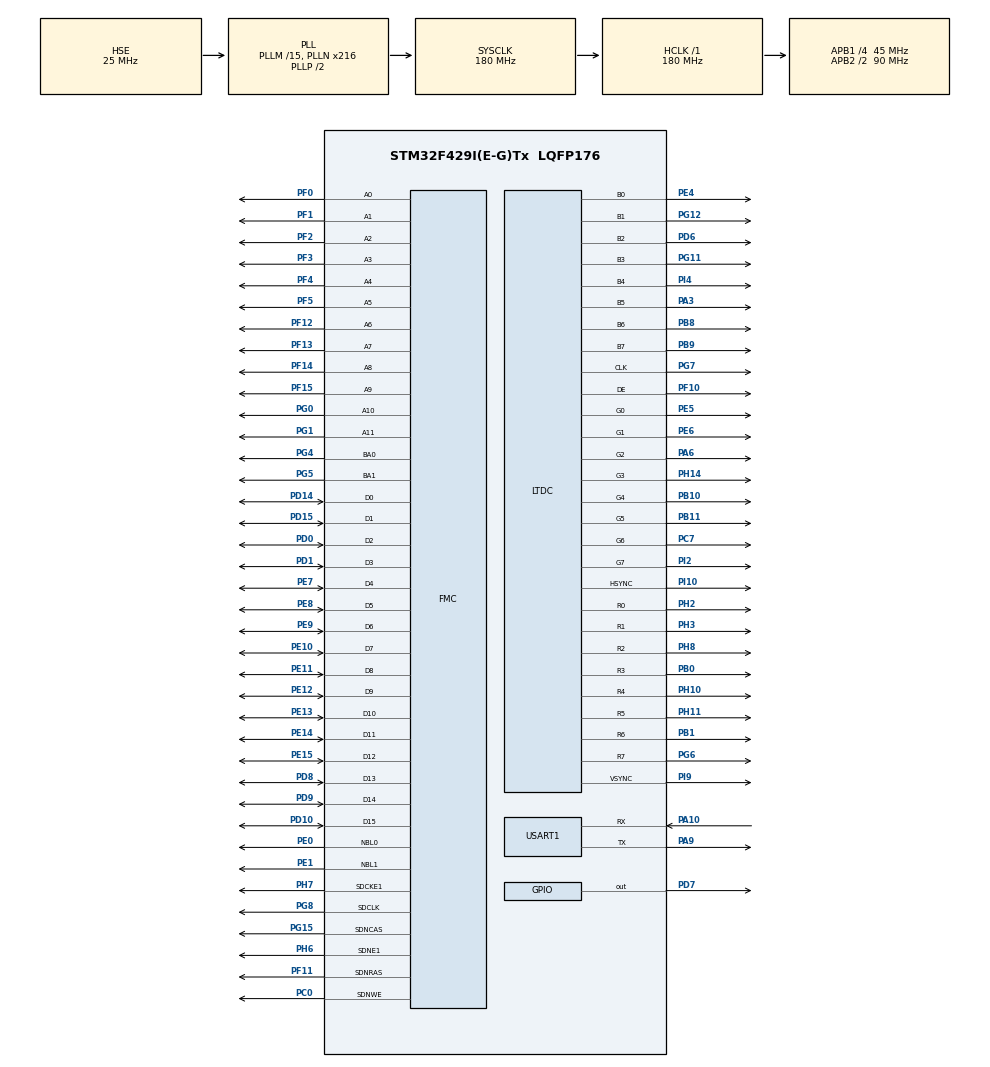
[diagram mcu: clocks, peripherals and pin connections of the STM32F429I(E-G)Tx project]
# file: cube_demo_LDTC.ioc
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DMA2D.ColorMode=DMA2D_OUTPUT_RGB565
Dma.MEMTOMEM.0.Direction=DMA_MEMORY_TO_MEMORY
Dma.MEMTOMEM.0.FIFOMode=DMA_FIFOMODE_ENABLE
Dma.MEMTOMEM.0.FIFOThreshold=DMA_FIFO_THRESHOLD_FULL
Dma.MEMTOMEM.0.Instance=DMA2_Stream0
Dma.MEMTOMEM.0.MemBurst=DMA_MBURST_SINGLE
Dma.MEMTOMEM.0.MemDataAlignment=DMA_MDATAALIGN_WORD
Dma.MEMTOMEM.0.MemInc=DMA_MINC_ENABLE
Dma.MEMTOMEM.0.Mode=DMA_NORMAL
Dma.MEMTOMEM.0.PeriphBurst=DMA_PBURST_SINGLE
Dma.MEMTOMEM.0.PeriphDataAlignment=DMA_PDATAALIGN_WORD
Dma.MEMTOMEM.0.PeriphInc=DMA_PINC_ENABLE
Dma.MEMTOMEM.0.Priority=DMA_PRIORITY_LOW
Dma.Request0=MEMTOMEM
FMC.CASLatency1=FMC_SDRAM_CAS_LATENCY_2
FMC.ExitSelfRefreshDelay1=8
FMC.LoadToActiveDelay1=2
FMC.RCDDelay1=3
FMC.RPDelay1=2
FMC.RPDelay2=2
FMC.RowCycleDelay1=7
FMC.RowCycleDelay2=7
FMC.SDClockPeriod1=FMC_SDRAM_CLOCK_PERIOD_2
FMC.SDClockPeriod2=FMC_SDRAM_CLOCK_PERIOD_2
FMC.SelfRefreshTime1=5
FMC.WriteRecoveryTime1=2
LTDC.ActiveW=800
LTDC.Alpha0_L0=0
LTDC.Alpha_L0=255
LTDC.Blue_L0=0
LTDC.FBStartAdress_L0=0xD0000000
LTDC.HBP=140
LTDC.HFP=160
LTDC.HSPolarity=LTDC_HSPOLARITY_AL
LTDC.HSync=20
LTDC.ImageHeight_L0=480
LTDC.ImageWidth_L0=800
LTDC.Layers=0
LTDC.PixelFormat_L0=LTDC_PIXEL_FORMAT_RGB565
LTDC.VBP=20
LTDC.VFP=12
LTDC.VSync=3
LTDC.WindowX1_L0=800
LTDC.WindowY1_L0=480
Mcu.Family=STM32F4
Mcu.Name=STM32F429I(E-G)Tx
Mcu.Package=LQFP176
NVIC.DMA2D_IRQn=true\:0\:0\:false\:false\:true\:true\:true
NVIC.LTDC_IRQn=true\:0\:0\:false\:false\:true\:true\:true
NVIC.PriorityGroup=NVIC_PRIORITYGROUP_4
PA10.Mode=Asynchronous
PA10.Signal=USART1_RX
PA13.Mode=Serial_Wire
PA13.Signal=SYS_JTMS-SWDIO
PA14.Mode=Serial_Wire
PA14.Signal=SYS_JTCK-SWCLK
PA3.GPIO_Speed=GPIO_SPEED_FREQ_HIGH
PA3.Mode=RGB888
PA3.Signal=LTDC_B5
PA6.GPIO_Speed=GPIO_SPEED_FREQ_HIGH
PA6.Mode=RGB888
PA6.Signal=LTDC_G2
PA9.Mode=Asynchronous
PA9.Signal=USART1_TX
PB0.GPIO_Speed=GPIO_SPEED_FREQ_HIGH
PB0.Mode=RGB888
PB0.Signal=LTDC_R3
PB1.GPIO_Speed=GPIO_SPEED_FREQ_HIGH
PB1.Mode=RGB888
PB1.Signal=LTDC_R6
PB10.GPIO_Speed=GPIO_SPEED_FREQ_HIGH
PB10.Mode=RGB888
PB10.Signal=LTDC_G4
PB11.GPIO_Speed=GPIO_SPEED_FREQ_HIGH
PB11.Mode=RGB888
PB11.Signal=LTDC_G5
PB8.GPIO_Speed=GPIO_SPEED_FREQ_HIGH
PB8.Mode=RGB888
PB8.Signal=LTDC_B6
PB9.GPIO_Speed=GPIO_SPEED_FREQ_HIGH
PB9.Mode=RGB888
PB9.Signal=LTDC_B7
PC0.Signal=FMC_SDNWE
PC7.GPIO_Speed=GPIO_SPEED_FREQ_HIGH
PC7.Mode=RGB888
PC7.Signal=LTDC_G6
PD0.Signal=FMC_D2_DA2
PD1.Signal=FMC_D3_DA3
PD10.Signal=FMC_D15_DA15
PD14.Signal=FMC_D0_DA0
PD15.Signal=FMC_D1_DA1
PD6.Mode=RGB888
PD6.Signal=LTDC_B2
PD7.GPIO_Speed=GPIO_SPEED_FREQ_HIGH
PD7.PinState=GPIO_PIN_SET
PD7.Signal=GPIO_Output
PD8.Signal=FMC_D13_DA13
PD9.Signal=FMC_D14_DA14
PE0.Signal=FMC_NBL0
PE1.Signal=FMC_NBL1
PE10.Signal=FMC_D7_DA7
PE11.Signal=FMC_D8_DA8
PE12.Signal=FMC_D9_DA9
PE13.Signal=FMC_D10_DA10
PE14.Signal=FMC_D11_DA11
PE15.Signal=FMC_D12_DA12
PE4.Mode=RGB888
PE4.Signal=LTDC_B0
PE5.Mode=RGB888
PE5.Signal=LTDC_G0
PE6.Mode=RGB888
PE6.Signal=LTDC_G1
PE7.Signal=FMC_D4_DA4
PE8.Signal=FMC_D5_DA5
PE9.Signal=FMC_D6_DA6
PF0.Signal=FMC_A0
PF1.Signal=FMC_A1
PF10.GPIO_Speed=GPIO_SPEED_FREQ_HIGH
PF10.Mode=RGB888
PF10.Signal=LTDC_DE
PF11.Signal=FMC_SDNRAS
PF12.Signal=FMC_A6
PF13.Signal=FMC_A7
PF14.Signal=FMC_A8
PF15.Signal=FMC_A9
PF2.Signal=FMC_A2
PF3.Signal=FMC_A3
PF4.Signal=FMC_A4
PF5.Signal=FMC_A5
PG0.Signal=FMC_A10
PG1.Signal=FMC_A11
PG11.GPIO_Speed=GPIO_SPEED_FREQ_HIGH
PG11.Mode=RGB888
PG11.Signal=LTDC_B3
PG12.Mode=RGB888
PG12.Signal=LTDC_B1
PG15.Signal=FMC_SDNCAS
PG4.Signal=FMC_A14_BA0
PG5.Signal=FMC_A15_BA1
PG6.GPIO_Speed=GPIO_SPEED_FREQ_HIGH
PG6.Mode=RGB888
PG6.Signal=LTDC_R7
PG7.GPIO_Speed=GPIO_SPEED_FREQ_HIGH
PG7.Mode=RGB888
PG7.Signal=LTDC_CLK
PG8.Signal=FMC_SDCLK
PH0/OSC_IN.Mode=HSE-External-Oscillator
PH0/OSC_IN.Signal=RCC_OSC_IN
PH1/OSC_OUT.Mode=HSE-External-Oscillator
PH1/OSC_OUT.Signal=RCC_OSC_OUT
PH10.GPIO_Speed=GPIO_SPEED_FREQ_HIGH
PH10.Mode=RGB888
PH10.Signal=LTDC_R4
PH11.GPIO_Speed=GPIO_SPEED_FREQ_HIGH
PH11.Mode=RGB888
PH11.Signal=LTDC_R5
PH14.GPIO_Speed=GPIO_SPEED_FREQ_HIGH
PH14.Mode=RGB888
PH14.Signal=LTDC_G3
PH2.Mode=RGB888
PH2.Signal=LTDC_R0
PH3.Mode=RGB888
PH3.Signal=LTDC_R1
PH6.Mode=SdramChipSelect2_1
PH6.Signal=FMC_SDNE1
PH7.Mode=SdramChipSelect2_1
PH7.Signal=FMC_SDCKE1
PH8.Mode=RGB888
PH8.Signal=LTDC_R2
PI10.GPIO_Speed=GPIO_SPEED_FREQ_HIGH
PI10.Mode=RGB888
PI10.Signal=LTDC_HSYNC
PI2.GPIO_Speed=GPIO_SPEED_FREQ_HIGH
PI2.Mode=RGB888
PI2.Signal=LTDC_G7
PI4.GPIO_Speed=GPIO_SPEED_FREQ_HIGH
PI4.Mode=RGB888
PI4.Signal=LTDC_B4
PI9.GPIO_Speed=GPIO_SPEED_FREQ_HIGH
PI9.Mode=RGB888
PI9.Signal=LTDC_VSYNC
ProjectManager.HeapSize=0x200
ProjectManager.StackSize=0x400
ProjectManager.TargetToolchain=MDK-ARM V5
RCC.48MHZClocksFreq_Value=90000000
RCC.AHBFreq_Value=180000000
RCC.APB1CLKDivider=RCC_HCLK_DIV4
RCC.APB1Freq_Value=45000000
RCC.APB1TimFreq_Value=90000000
RCC.APB2CLKDivider=RCC_HCLK_DIV2
RCC.APB2Freq_Value=90000000
RCC.APB2TimFreq_Value=180000000
RCC.CortexFreq_Value=180000000
RCC.HCLKFreq_Value=180000000
RCC.HSE_VALUE=25000000
RCC.HSI_VALUE=16000000
RCC.LSE_VALUE=32768
RCC.PLLM=15
RCC.PLLN=216
RCC.PLLSAIN=60
RCC.PLLSourceVirtual=RCC_PLLSOURCE_HSE
RCC.SYSCLKFreq_VALUE=180000000
RCC.SYSCLKSource=RCC_SYSCLKSOURCE_PLLCLK
RCC.VCOOutputFreq_Value=360000000
SH.FMC_A0.0=FMC_A0,12b-sda1
SH.FMC_A1.0=FMC_A1,12b-sda1
SH.FMC_A10.0=FMC_A10,12b-sda1
SH.FMC_A11.0=FMC_A11,12b-sda1
SH.FMC_A14_BA0.0=FMC_BA0,FourSdramBanks1
SH.FMC_A15_BA1.0=FMC_BA1,FourSdramBanks1
SH.FMC_A2.0=FMC_A2,12b-sda1
SH.FMC_A3.0=FMC_A3,12b-sda1
SH.FMC_A4.0=FMC_A4,12b-sda1
SH.FMC_A5.0=FMC_A5,12b-sda1
SH.FMC_A6.0=FMC_A6,12b-sda1
SH.FMC_A7.0=FMC_A7,12b-sda1
SH.FMC_A8.0=FMC_A8,12b-sda1
SH.FMC_A9.0=FMC_A9,12b-sda1
SH.FMC_D0_DA0.0=FMC_D0,sd-16b-d1
SH.FMC_D10_DA10.0=FMC_D10,sd-16b-d1
SH.FMC_D11_DA11.0=FMC_D11,sd-16b-d1
SH.FMC_D12_DA12.0=FMC_D12,sd-16b-d1
SH.FMC_D13_DA13.0=FMC_D13,sd-16b-d1
SH.FMC_D14_DA14.0=FMC_D14,sd-16b-d1
SH.FMC_D15_DA15.0=FMC_D15,sd-16b-d1
SH.FMC_D1_DA1.0=FMC_D1,sd-16b-d1
SH.FMC_D2_DA2.0=FMC_D2,sd-16b-d1
SH.FMC_D3_DA3.0=FMC_D3,sd-16b-d1
SH.FMC_D4_DA4.0=FMC_D4,sd-16b-d1
SH.FMC_D5_DA5.0=FMC_D5,sd-16b-d1
SH.FMC_D6_DA6.0=FMC_D6,sd-16b-d1
SH.FMC_D7_DA7.0=FMC_D7,sd-16b-d1
SH.FMC_D8_DA8.0=FMC_D8,sd-16b-d1
SH.FMC_D9_DA9.0=FMC_D9,sd-16b-d1
SH.FMC_NBL0.0=FMC_NBL0,Sd2ByteEnable1
SH.FMC_NBL1.0=FMC_NBL1,Sd2ByteEnable1
SH.FMC_SDCLK.0=FMC_SDCLK,12b-sda1
SH.FMC_SDNCAS.0=FMC_SDNCAS,12b-sda1
SH.FMC_SDNRAS.0=FMC_SDNRAS,12b-sda1
SH.FMC_SDNWE.0=FMC_SDNWE,12b-sda1
USART1.VirtualMode=VM_ASYNC
VP_DMA2D_VS_DMA2D.Mode=DMA2D_Activate
board=custom

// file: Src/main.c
/* USER CODE BEGIN Header */
/**
  ******************************************************************************
  * @file           : main.c
  * @brief          : Main program body
  ******************************************************************************
  * @attention
  *
  * <h2><center>&copy; Copyright (c) 2019 STMicroelectronics.
  * All rights reserved.</center></h2>
  *
  * This software component is licensed by ST under BSD 3-Clause license,
  * the "License"; You may not use this file except in compliance with the
  * License. You may obtain a copy of the License at:
  *                        opensource.org/licenses/BSD-3-Clause
  *
  ******************************************************************************
  */
/* USER CODE END Header */

#include "main.h"
#include "dma.h"
#include "dma2d.h"
#include "ltdc.h"
#include "usart.h"
#include "gpio.h"
#include "fmc.h"

/* USER CODE BEGIN Includes */
#include "stm32746g_sdram.h"
#include "dji.h"
/* USER CODE END Includes */

void SystemClock_Config(void);
/* USER CODE BEGIN PFP */
#define BUFFER_SIZE         ((uint32_t)0x0100)
#define WRITE_READ_ADDR     ((uint32_t)0x0800)
/* Read/Write Buffers */
uint32_t aTxBuffer[BUFFER_SIZE];
uint32_t aRxBuffer[BUFFER_SIZE];
uint32_t buffer[300];
__IO uint32_t checkWriteReadStatus = 0;
int i;
/* USER CODE END PFP */

int main(void)
{

  /* MCU Configuration--------------------------------------------------------*/

  /* Reset of all peripherals, Initializes the Flash interface and the Systick. */
  HAL_Init();

  /* Configure the system clock */
  SystemClock_Config();

  /* Initialize all configured peripherals */
  MX_GPIO_Init();
  MX_DMA_Init();
  MX_FMC_Init();
  MX_USART1_UART_Init();
  MX_DMA2D_Init();
  MX_LTDC_Init();
  /* USER CODE BEGIN 2 */
  printf("\r\n LDTC DMA2D example !!!\r\n");
  /* SDRAM device configuration */
  BSP_SDRAM_Initialization_sequence(REFRESH_COUNT);

  /* 1- SDRAM memory read/write access test  */
  /* Fill the buffer to write */
  for (i = 0; i < BUFFER_SIZE; i++)
  {
    aTxBuffer[i] = 0x00000000 + i; /* TxBuffer init */
  }

  /* Write data to the SDRAM memory */
  BSP_SDRAM_WriteData(SDRAM_DEVICE_ADDR + WRITE_READ_ADDR, aTxBuffer, BUFFER_SIZE);
  printf("\r\n/* Write data to the SDRAM memory */\r\n\r\n");
  for (i = 0; i < BUFFER_SIZE; i++)
  {
    printf("%02X:0x%08X ", i, aTxBuffer[i]);
  }
  printf("\r\n");

  /* Read back data from the SDRAM memory */
  BSP_SDRAM_ReadData(SDRAM_DEVICE_ADDR + WRITE_READ_ADDR, aRxBuffer, BUFFER_SIZE);
  printf("\r\n/* Read back data from the SDRAM memory */\r\n\r\n");
  for (i = 0; i < BUFFER_SIZE; i++)
  {
    printf("%02X:0x%08X ", i, aRxBuffer[i]);
  }
  printf("\r\n");

  /* 2- Checking data integrity */
  for (i = 0; (i < BUFFER_SIZE); i++)
  {
    if (aRxBuffer[i] != aTxBuffer[i])
      checkWriteReadStatus++;
  }
  if (checkWriteReadStatus == 0) /* check date */
    printf("\r\n SDRAM Test OK\r\n");
  else
    printf("\r\n SDRAM Test False\r\n");

  HAL_GPIO_WritePin(GPIOD, GPIO_PIN_7, GPIO_PIN_SET);//lighting the back light
  printf("Backlight = %d !!!", HAL_GPIO_ReadPin(GPIOD, GPIO_PIN_7));
  /* 3- Start DMA2D transfer */
  if(HAL_DMA2D_Start_IT(&hdma2d, (uint32_t)_acDJI_0002, (uint32_t)0xD0000000, 800, 480) != HAL_OK)  //(uint32_t)SDRAM_DEVICE_ADDR
  {
  }
  HAL_Delay(500);

  /* Read back data from the SDRAM memory */
  BSP_SDRAM_ReadData(SDRAM_DEVICE_ADDR, buffer, 300);
  printf("\r\n/* Read back data from the SDRAM memory */\r\n\r\n");
  for(i=0;i< BUFFER_SIZE;i++)
  {
        printf("%02X:0x%08X ",i,buffer[i]);
  }
  printf("\r\n");
  /* USER CODE END 2 */

  /* Infinite loop */
  while (1)
  {

  }
}

void SystemClock_Config(void)
{
  RCC_OscInitTypeDef RCC_OscInitStruct = {0};
  RCC_ClkInitTypeDef RCC_ClkInitStruct = {0};
  RCC_PeriphCLKInitTypeDef PeriphClkInitStruct = {0};

  /** Configure the main internal regulator output voltage
  */
  __HAL_RCC_PWR_CLK_ENABLE();
  __HAL_PWR_VOLTAGESCALING_CONFIG(PWR_REGULATOR_VOLTAGE_SCALE1);
  /** Initializes the CPU, AHB and APB busses clocks
  */
  RCC_OscInitStruct.OscillatorType = RCC_OSCILLATORTYPE_HSE;
  RCC_OscInitStruct.HSEState = RCC_HSE_ON;
  RCC_OscInitStruct.PLL.PLLState = RCC_PLL_ON;
  RCC_OscInitStruct.PLL.PLLSource = RCC_PLLSOURCE_HSE;
  RCC_OscInitStruct.PLL.PLLM = 15;
  RCC_OscInitStruct.PLL.PLLN = 216;
  RCC_OscInitStruct.PLL.PLLP = RCC_PLLP_DIV2;
  RCC_OscInitStruct.PLL.PLLQ = 4;
  if (HAL_RCC_OscConfig(&RCC_OscInitStruct) != HAL_OK)
  {
    Error_Handler();
  }
  /** Activate the Over-Drive mode
  */
  if (HAL_PWREx_EnableOverDrive() != HAL_OK)
  {
    Error_Handler();
  }
  /** Initializes the CPU, AHB and APB busses clocks
  */
  RCC_ClkInitStruct.ClockType = RCC_CLOCKTYPE_HCLK|RCC_CLOCKTYPE_SYSCLK
                              |RCC_CLOCKTYPE_PCLK1|RCC_CLOCKTYPE_PCLK2;
  RCC_ClkInitStruct.SYSCLKSource = RCC_SYSCLKSOURCE_PLLCLK;
  RCC_ClkInitStruct.AHBCLKDivider = RCC_SYSCLK_DIV1;
  RCC_ClkInitStruct.APB1CLKDivider = RCC_HCLK_DIV4;
  RCC_ClkInitStruct.APB2CLKDivider = RCC_HCLK_DIV2;

  if (HAL_RCC_ClockConfig(&RCC_ClkInitStruct, FLASH_LATENCY_5) != HAL_OK)
  {
    Error_Handler();
  }
  PeriphClkInitStruct.PeriphClockSelection = RCC_PERIPHCLK_LTDC;
  PeriphClkInitStruct.PLLSAI.PLLSAIN = 60;
  PeriphClkInitStruct.PLLSAI.PLLSAIR = 2;
  PeriphClkInitStruct.PLLSAIDivR = RCC_PLLSAIDIVR_2;
  if (HAL_RCCEx_PeriphCLKConfig(&PeriphClkInitStruct) != HAL_OK)
  {
    Error_Handler();
  }
}

void Error_Handler(void)
{
}

/************************ (C) COPYRIGHT STMicroelectronics *****END OF FILE****/
